# PIC32CZ2051CA90176S1 device description
Architecture: CORTEX-M0PLUS; Family: PIC32CZ; Series: PIC32CZCA90
Registers are 32-bit, read-write, reset 0x0 unless marked. A register's access mark holds for its fields unless they carry their own. Offsets are from the block's base; [hi:lo] are bit positions; {n}, {i} and the like mark numbered series; 'fields as' and 'values as' point back to an identical list.

## PKRAM — PKRAM Module
Instances: PKRAM 0x57000200
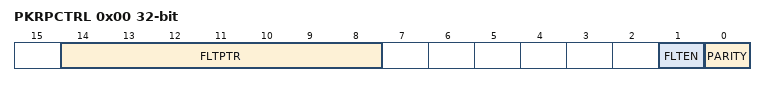
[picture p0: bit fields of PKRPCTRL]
0x00 PKRPCTRL — Parity Control
  [14:8] FLTPTR — Fault Injection Bit Pointer bit
  [1] FLTEN — Fault Injection Enable bit
  [0] PARITY — RAM Parity Enable bit (1)
0x04 PKRPERROR ro — Parity Error
  [0] PARITY — PK RAM Parity Error bit

## RTC — Real Time Clock Module
Instances: RTC 0x59000000
0x00 CNTL — Lower Count
  [31:17] CNTL — RTC Lower Counter Register
0x04 CNTH — Upper Count
  [31:0] CNTH — RTC Upper Counter Register
0x08 MATCHL — Lower Match
  [31:17] MATCHL — RTC Match Register
0x0C MATCHH — UpperMatch
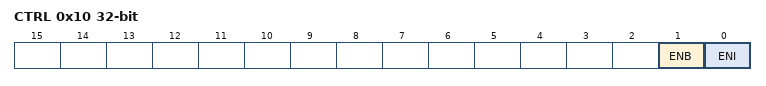
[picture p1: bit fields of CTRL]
0x10 CTRL — Control
  [1] ENB, [0] ENI
0x14 STAT ro — Status
  [0] STAT — Raw match status

## SYSREGS — eSecure System Registers Module
Instances: SYSREGS 0x52001C00
0x0C POWERCTRL — Power Control
  [2:0] STATE — Power Control State
    1=ESECBOOTDONE (ESecure Boot is Finished); 2=POWERDOWN (ESecure is in Power-down); 3=HOSTBOOTDONE (Host Boot is Finished); 4=IDLE (ESecure is Idle); 5=BUSY (ESecure is Busy)

## SysTick — System timer
Instances: SysTick 0xE000E010
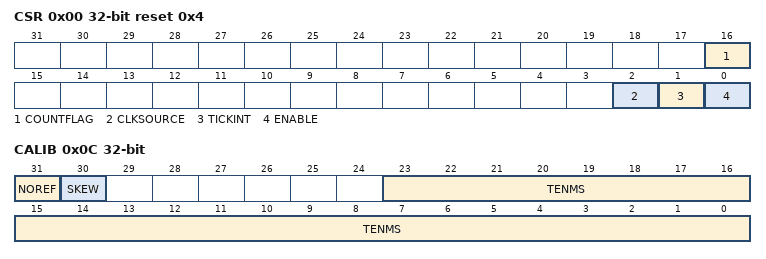
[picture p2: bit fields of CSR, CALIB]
0x00 CSR reset 0x4 — SysTick Control and Status Register
  [16] COUNTFLAG — Timer counted to 0 since last read of register
  [2] CLKSOURCE — Clock Source 0=external, 1=processor
    0=External clock; 1=Processor clock
  [1] TICKINT — SysTick Exception Request Enable
    0=Counting down to 0 does not assert the SysTick exception request; 1=Counting down to 0 asserts the SysTick exception request
  [0] ENABLE — SysTick Counter Enable
    0=Counter disabled; 1=Counter enabled
0x04 RVR reset not defined — SysTick Reload Value Register
  [23:0] RELOAD — Value to load into the SysTick Current Value Register when the counter reaches 0
0x08 CVR reset not defined — SysTick Current Value Register
  [23:0] CURRENT — Current value at the time the register is accessed
0x0C CALIB ro — SysTick Calibration Value Register
  [31] NOREF — No Separate Reference Clock
    0=The reference clock is provided; 1=The reference clock is not provided
  [30] SKEW — TENMS is rounded from non-integer ratio
    0=10ms calibration value is exact; 1=10ms calibration value is inexact, because of the clock frequency
  [23:0] TENMS — Reload value to use for 10ms timing

## SystemControl — System Control Registers
Instances: SystemControl 0xE000E000
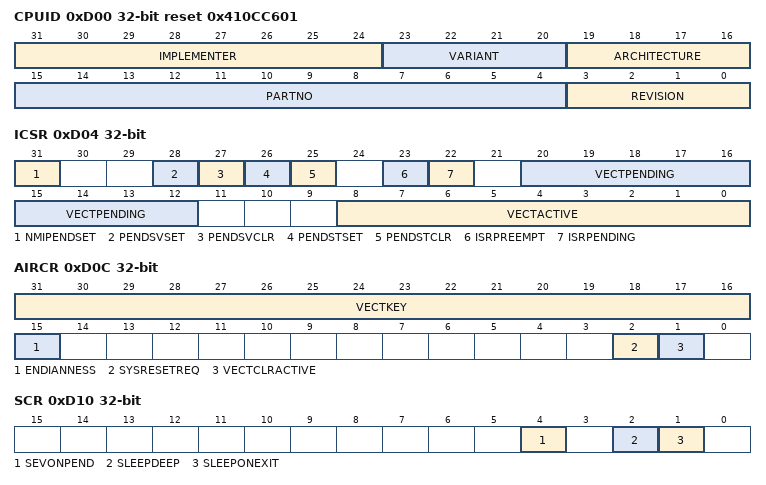
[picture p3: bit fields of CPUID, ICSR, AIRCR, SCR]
0xD00 CPUID ro reset 0x410CC601 — CPUID Base Register
  [31:24] IMPLEMENTER — Implementer code, ARM=0x41
  [23:20] VARIANT — Major revision number
  [19:16] ARCHITECTURE — Processor Architecture, 0xC=ARMv6-M
  [15:4] PARTNO — Processor Part Number, 0xC60=Cortex-M0+
  [3:0] REVISION — Minor revision number
0xD04 ICSR — Interrupt Control and State Register
  [31] NMIPENDSET — NMI set-pending bit
    0=Write: no effect; read: NMI exception is not pending; 1=Write: changes NMI exception state to pending; read: NMI exception is pending
  [28] PENDSVSET — PendSV set-pending bit
    0=Write: no effect; read: PendSV exception is not pending; 1=Write: changes PendSV exception state to pending; read: PendSV exception is pending
  [27] PENDSVCLR — PendSV clear-pending bit
    0=No effect; 1=Removes the pending state from the PendSV exception
  [26] PENDSTSET — SysTick exception set-pending bit
    0=Write: no effect; read: SysTick exception is not pending; 1=Write: changes SysTick exception state to pending; read: SysTick exception is pending
  [25] PENDSTCLR — SysTick exception clear-pending bit
    0=No effect; 1=Removes the pending state from the SysTick exception
  [23] ISRPREEMPT — Debug: Pending exception serviced on exit from debug halt
  [22] ISRPENDING — Debug: NVIC interrupt pending
  [20:12] VECTPENDING — Exception number of the highest priority pending enabled exception
  [8:0] VECTACTIVE — Debug: Exception number of currently executing exception, or 0 if thread mode
0xD08 VTOR — Vector Table Offset Register
  [31:7] TBLOFF — Vector table base offset
0xD0C AIRCR — Application Interrupt and Reset Control Register
  [31:16] VECTKEY — Register key (0x05FA)
  [15] ENDIANNESS — Data Endianness, 0=little, 1=big
    0=Little-endian; 1=Big-endian
  [2] SYSRESETREQ — System Reset Request
    0=No system reset request; 1=Asserts a signal to the outer system that requests a reset
  [1] VECTCLRACTIVE — Debug: Clear state information
0xD10 SCR — System Control Register
  [4] SEVONPEND — Send Event on Pending bit
    0=Only enabled interrupts or events can wakeup the processor, disabled interrupts are excluded; 1=Enabled events and all interrupts, including disabled interrupts, can wakeup the processor
  [2] SLEEPDEEP — Uses Deep Sleep as low power mode
    0=Sleep; 1=Deep sleep
  [1] SLEEPONEXIT — Sleep-On-Exit when exiting Handler mode
    0=O not sleep when returning to Thread mode; 1=Enter sleep, or deep sleep, on return from an ISR
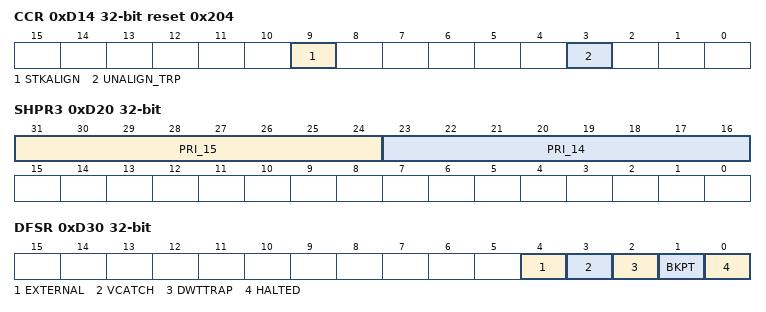
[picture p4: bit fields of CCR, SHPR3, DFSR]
0xD14 CCR ro reset 0x204 — Configuration and Control Register
  [9] STKALIGN — Stack 8-byte aligned on exception entry
    0=4-byte aligned; 1=8-byte aligned
  [3] UNALIGN_TRP — Unaligned accesses generates a Hard Fault
    0=Do not trap unaligned halfword and word accesses; 1=Trap unaligned halfword and word accesses
0xD1C SHPR2 — System Handler Priority Register 2
  [31:24] PRI_11 — Priority of system handler 11, SVCall
0xD20 SHPR3 — System Handler Priority Register 3
  [31:24] PRI_15 — Priority of system handler 15, SysTick exception
  [23:16] PRI_14 — Priority of system handler 14, PendSV
0xD24 SHCSR — System Handler Control and State Register
  [15] SVCALLPENDED
0xD30 DFSR — Debug Fault Status Register
  [4] EXTERNAL — EDBGRQ debug event
  [3] VCATCH — Vector catch debug event
  [2] DWTTRAP — DWT debug event
  [1] BKPT — Breakpoint debug event
  [0] HALTED — Halt request debug event active

## TAMPER — eSecure IP Core Anti-tampering
Instances: TAMPER 0x59000400
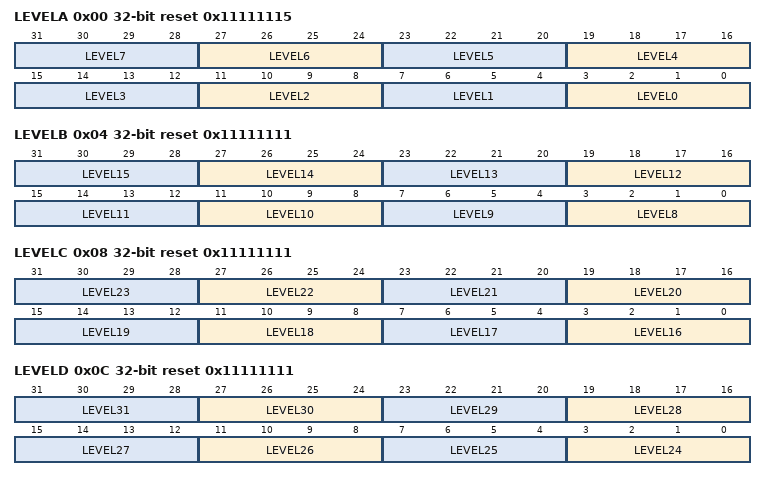
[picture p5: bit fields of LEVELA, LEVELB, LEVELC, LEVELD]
0x00 LEVELA ro reset 0x11111115
  [all] fields
    0=NONE (No Action); 1=HOSTIRQ (Host Interrupt); 2=LEHIRQ (Log Event and Host Interrupt); 4=SAFEMODE (Enter Safe Mode); 5=ERSTKEY (Erase Tamper Key); 6=ERSFKEY (Erase Flash Key)
  [4n+3:4n] LEVEL{n} (n=0..7)
0x04 LEVELB ro reset 0x11111111
  [all] fields
    values as the fields of LEVELA
  [4n-29:4n-32] LEVEL{n} (n=8..15)
0x08 LEVELC ro reset 0x11111111
  [all] fields
    values as the fields of LEVELA
  [4n-61:4n-64] LEVEL{n} (n=16..23)
0x0C LEVELD ro reset 0x11111111
  [all] fields
    values as the fields of LEVELA
  [4n-93:4n-96] LEVEL{n} (n=24..31)
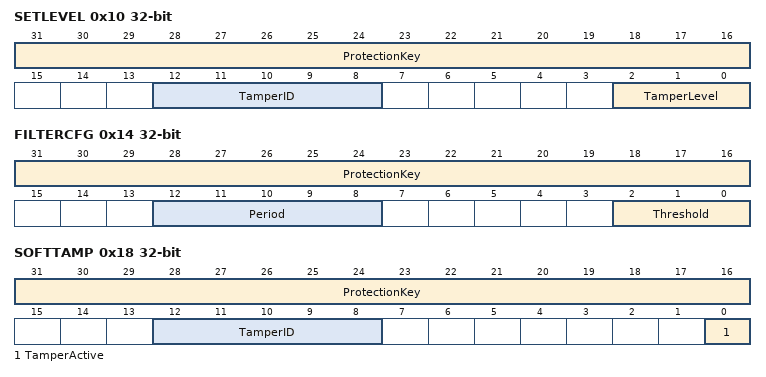
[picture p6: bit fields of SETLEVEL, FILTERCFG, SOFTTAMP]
0x10 SETLEVEL wo
  [31:16] ProtectionKey, [12:8] TamperID, [2:0] TamperLevel
0x14 FILTERCFG — Filter Configuraiton
  [31:16] ProtectionKey — Filter Protection Key
  [12:8] Period — Filter Period
  [2:0] Threshold — Filter Threshold
0x18 SOFTTAMP — Soft Tamper
  [31:16] ProtectionKey, [12:8] TamperID, [0] TamperActive
0x1C RAWSTAT ro — Raw Status
0x20 STAT reset 0x1 — Status
0x24 TIMESTAMP ro
0x28 FILTERCNT ro — Filter Count
0x2C SOFTINFO — Soft Information
0x30 HOSTIRQ — Host Interrupt
0x34 SOFTRESET ro (atomic set)

## TIMERS — Timer Module
Instances: TIMERS 0x52001800
0x00 RST reset not defined — Reset
0x04 STOP reset not defined
0x08 INTEN reset not defined — Interrupt Enable
0x0C INTDIS reset not defined — Interrupt Disable
0x10 STAT reset not defined — Status
0x18 CNT0 reset not defined — Counter 0
0x1C MATCH0 reset not defined
0x20 CNT1 reset not defined — Counter 1
0x24 MATCH1 reset not defined

## WDT — Watchdog Timer Module
Instances: WDT 0x52000C00
0x00 WDCOUNT ro reset not defined — Count
0x04 WDRELOAD reset not defined — Reload
0x08 WDKICK wo reset not defined — Kick
0x0C WDCONTROL — Control
  [0] WDRSTEN
0x10 WDSTATUS ro reset not defined — Status
0x14 WDSTOP wo reset not defined — Stop
